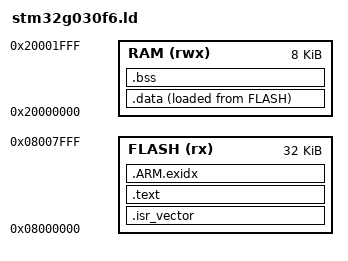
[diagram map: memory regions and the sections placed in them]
ENTRY(Reset_Handler)
MEMORY {
  FLASH (rx) : ORIGIN = 0x08000000, LENGTH = 32K
  RAM (rwx) : ORIGIN = 0x20000000, LENGTH = 8K
}
_estack = ORIGIN(RAM) + LENGTH(RAM);
_stack_limit = _estack - 2048;
SECTIONS {
  .isr_vector : { . = ALIGN(256); KEEP(*(.isr_vector)) } > FLASH
  .text : { *(.text*) *(.rodata*) . = ALIGN(4); } > FLASH
  .ARM.exidx : { *(.ARM.exidx*) } > FLASH
  .data : {
    . = ALIGN(4); _sdata = .; *(.data*) . = ALIGN(4); _edata = .;
  } > RAM AT> FLASH
  _sidata = LOADADDR(.data);
  .bss (NOLOAD) : {
    . = ALIGN(4); _sbss = .; *(.bss*) *(COMMON) . = ALIGN(4); _ebss = .;
  } > RAM
  _end = .;
  /DISCARD/ : { *(.comment*) *(.note*) }
}
ASSERT(_end <= _stack_limit, "STM32G030F6 RAM exceeds reserved 2KiB stack envelope")
ASSERT(LOADADDR(.data) + SIZEOF(.data) <= ORIGIN(FLASH) + LENGTH(FLASH), "STM32G030F6 flash overflow")
